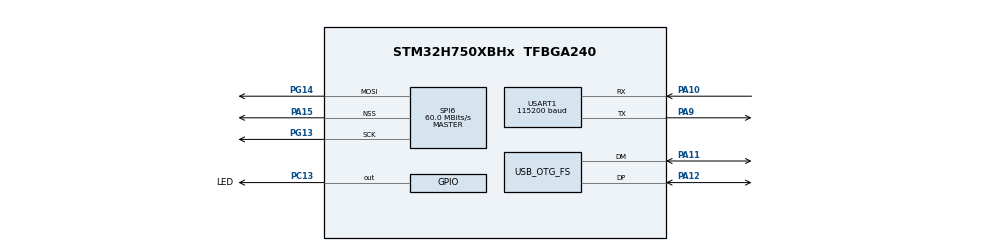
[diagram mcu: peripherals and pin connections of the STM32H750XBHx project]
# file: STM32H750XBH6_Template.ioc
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Bdma.Request0=SPI6_TX
Bdma.RequestsNb=1
Bdma.SPI6_TX.0.Direction=DMA_MEMORY_TO_PERIPH
Bdma.SPI6_TX.0.EventEnable=DISABLE
Bdma.SPI6_TX.0.Instance=BDMA_Channel0
Bdma.SPI6_TX.0.MemDataAlignment=DMA_MDATAALIGN_BYTE
Bdma.SPI6_TX.0.MemInc=DMA_MINC_ENABLE
Bdma.SPI6_TX.0.Mode=DMA_NORMAL
Bdma.SPI6_TX.0.PeriphDataAlignment=DMA_PDATAALIGN_BYTE
Bdma.SPI6_TX.0.PeriphInc=DMA_PINC_DISABLE
Bdma.SPI6_TX.0.Polarity=HAL_DMAMUX_REQ_GEN_RISING
Bdma.SPI6_TX.0.Priority=DMA_PRIORITY_VERY_HIGH
Bdma.SPI6_TX.0.RequestNumber=1
Bdma.SPI6_TX.0.SignalID=NONE
Bdma.SPI6_TX.0.SyncEnable=DISABLE
Bdma.SPI6_TX.0.SyncPolarity=HAL_DMAMUX_SYNC_NO_EVENT
Bdma.SPI6_TX.0.SyncRequestNumber=1
Bdma.SPI6_TX.0.SyncSignalID=NONE
CORTEX_M7.CPU_DCache=Disabled
CORTEX_M7.CPU_ICache=Disabled
CORTEX_M7.MPU_Control=__NULL
CORTEX_M7.default_mode_Activation=0
Mcu.Family=STM32H7
Mcu.Name=STM32H750XBHx
Mcu.Package=TFBGA240
NVIC.BDMA_Channel0_IRQn=true\:0\:0\:false\:false\:true\:false\:true\:true
NVIC.OTG_FS_IRQn=true\:0\:0\:false\:false\:true\:false\:true\:true
NVIC.PriorityGroup=NVIC_PRIORITYGROUP_4
NVIC.SPI6_IRQn=true\:0\:0\:false\:false\:true\:false\:true\:true
NVIC.USART1_IRQn=true\:1\:0\:true\:false\:true\:true\:true\:true
PA10.Mode=Asynchronous
PA10.Signal=USART1_RX
PA11.Mode=Device_Only
PA11.Signal=USB_OTG_FS_DM
PA12.Mode=Device_Only
PA12.Signal=USB_OTG_FS_DP
PA13\ (JTMS/SWDIO).Mode=Serial_Wire
PA13\ (JTMS/SWDIO).Signal=DEBUG_JTMS-SWDIO
PA14\ (JTCK/SWCLK).Mode=Serial_Wire
PA14\ (JTCK/SWCLK).Signal=DEBUG_JTCK-SWCLK
PA15\ (JTDI).GPIO_Speed=GPIO_SPEED_FREQ_VERY_HIGH
PA15\ (JTDI).Mode=NSS_Signal_Hard_Output
PA15\ (JTDI).Signal=SPI6_NSS
PA9.Mode=Asynchronous
PA9.Signal=USART1_TX
PC13.GPIO_Label=LED
PC13.PinState=GPIO_PIN_SET
PC13.Signal=GPIO_Output
PC14-OSC32_IN\ (OSC32_IN).Mode=LSE-External-Oscillator
PC14-OSC32_IN\ (OSC32_IN).Signal=RCC_OSC32_IN
PC15-OSC32_OUT\ (OSC32_OUT).Mode=LSE-External-Oscillator
PC15-OSC32_OUT\ (OSC32_OUT).Signal=RCC_OSC32_OUT
PG13.GPIO_Speed=GPIO_SPEED_FREQ_VERY_HIGH
PG13.Mode=TX_Only_Simplex_Unidirect_Master
PG13.Signal=SPI6_SCK
PG14.GPIO_Speed=GPIO_SPEED_FREQ_VERY_HIGH
PG14.Mode=TX_Only_Simplex_Unidirect_Master
PG14.Signal=SPI6_MOSI
PH0-OSC_IN\ (PH0).Mode=HSE-External-Oscillator
PH0-OSC_IN\ (PH0).Signal=RCC_OSC_IN
PH1-OSC_OUT\ (PH1).Mode=HSE-External-Oscillator
PH1-OSC_OUT\ (PH1).Signal=RCC_OSC_OUT
ProjectManager.HeapSize=0x200
ProjectManager.StackSize=0x400
ProjectManager.TargetToolchain=CMake
RCC.ADCFreq_Value=480000000
RCC.APB1Freq_Value=120000000
RCC.APB2Freq_Value=120000000
RCC.APB3Freq_Value=120000000
RCC.APB4Freq_Value=120000000
RCC.CortexFreq_Value=480000000
RCC.D1PPRE=RCC_APB3_DIV2
RCC.D2PPRE1=RCC_APB1_DIV2
RCC.D2PPRE2=RCC_APB2_DIV2
RCC.D3PPRE=RCC_APB4_DIV2
RCC.DIVM1=5
RCC.DIVM2=5
RCC.DIVM3=5
RCC.DIVN1=192
RCC.DIVN2=192
RCC.DIVN3=192
RCC.FLatency=FLASH_LATENCY_4
RCC.HCLKFreq_Value=240000000
RCC.HPRE=RCC_HCLK_DIV2
RCC.PLL1_VCI_Range=RCC_PLL1VCIRANGE_2
RCC.PLL2FRACN=0
RCC.PLL3FRACN=0
RCC.PLLFRACN=0
RCC.PLLSourceVirtual=RCC_PLLSOURCE_HSE
RCC.PWR_Regulator_Voltage_Scale=PWR_REGULATOR_VOLTAGE_SCALE0
RCC.ProductRev=revV
RCC.SYSCLKFreq_VALUE=480000000
RCC.SYSCLKSource=RCC_SYSCLKSOURCE_PLLCLK
RCC.USBCLockSelection=RCC_USBCLKSOURCE_HSI48
RCC.USBFreq_Value=48000000
SPI6.CalculateBaudRate=60.0 MBits/s
SPI6.DataSize=SPI_DATASIZE_8BIT
SPI6.Direction=SPI_DIRECTION_2LINES_TXONLY
SPI6.Mode=SPI_MODE_MASTER
SPI6.VirtualNSS=VM_NSSHARD
SPI6.VirtualType=VM_MASTER
USART1.AutoBaudRateEnableParam=UART_ADVFEATURE_AUTOBAUDRATE_DISABLE
USART1.BaudRate=115200
USART1.ClockPrescaler=PRESCALER_DIV1
USART1.DMADisableonRxErrorParam=ADVFEATURE_DMA_ENABLEONRXERROR
USART1.DataInvertParam=ADVFEATURE_DATAINV_DISABLE
USART1.FIFOMode=FIFOMODE_DISABLE
USART1.MSBFirstParam=ADVFEATURE_MSBFIRST_DISABLE
USART1.Mode=MODE_TX_RX
USART1.OneBitSampling=UART_ONE_BIT_SAMPLE_DISABLE
USART1.OverSampling=UART_OVERSAMPLING_16
USART1.OverrunDisableParam=ADVFEATURE_OVERRUN_ENABLE
USART1.Parity=PARITY_NONE
USART1.RXFIFOThreshold=RXFIFO_THRESHOLD_1EIGHTHFULL
USART1.RxPinLevelInvertParam=ADVFEATURE_RXINV_DISABLE
USART1.StopBits=STOPBITS_1
USART1.SwapParam=ADVFEATURE_SWAP_DISABLE
USART1.TXFIFOThreshold=TXFIFO_THRESHOLD_1EIGHTHFULL
USART1.TxPinLevelInvertParam=ADVFEATURE_TXINV_DISABLE
USART1.VirtualMode-Asynchronous=VM_ASYNC
USART1.WordLength=WORDLENGTH_8B
USB_DEVICE.CLASS_NAME_FS=CDC
USB_DEVICE.VirtualMode-CDC_FS=Cdc
USB_DEVICE.VirtualModeFS=Cdc_FS
USB_OTG_FS.VirtualMode=Device_Only
VP_MEMORYMAP_VS_MEMORYMAP.Mode=CurAppReg
VP_USB_DEVICE_VS_USB_DEVICE_CDC_FS.Mode=CDC_FS
board=custom

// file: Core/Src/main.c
/* USER CODE BEGIN Header */
/**
 ******************************************************************************
 * @file           : main.c
 * @brief          : Main program body
 ******************************************************************************
 * @attention
 *
 * Copyright (c) 2025 STMicroelectronics.
 * All rights reserved.
 *
 * This software is licensed under terms that can be found in the LICENSE file
 * in the root directory of this software component.
 * If no LICENSE file comes with this software, it is provided AS-IS.
 *
 ******************************************************************************
 */
/* USER CODE END Header */
#include "main.h"
#include "bdma.h"
#include "spi.h"
#include "usart.h"
#include "usb_device.h"
#include "gpio.h"

/* USER CODE BEGIN Includes */
#include "lcd_spi_200.h"
#include "retarget.h" //重定向printf
#include "usbd_cdc_if.h"
#include "user_code_interface.h"
/* USER CODE END Includes */

void SystemClock_Config(void);

int main(void)
{

  /* MCU Configuration--------------------------------------------------------*/

  /* Reset of all peripherals, Initializes the Flash interface and the Systick. */
  HAL_Init();

  /* Configure the system clock */
  SystemClock_Config();

  /* Initialize all configured peripherals */
  MX_GPIO_Init();
  MX_BDMA_Init();
  MX_USART1_UART_Init();
  MX_USB_DEVICE_Init();
  MX_SPI6_Init();
  /* USER CODE BEGIN 2 */
    RetargetInit(&huart1); // 重定向printf
    SPI_LCD_Init();

    printf("现在进行刷屏测试\n");
    User_Code_Entry();

  /* USER CODE END 2 */

  /* Infinite loop */
    while (1)
    {

    /* USER CODE BEGIN 3 */
        // LCD_Test_Clear(); // 清屏测试
        // LCD_Test_Text(); // 文本测试
        // LCD_Test_Variable(); // 变量显示，包括整数和小数
        // LCD_Test_Color(); // 颜色测试
        // LCD_Test_Grahic(); // 2D图形绘制
        // LCD_Test_Image(); // 图片显示
        // LCD_Test_Direction(); // 更换显示方向
        HAL_Delay(500);
        printf("hello, world!\n");
    }
  /* USER CODE END 3 */
}

void SystemClock_Config(void)
{
  RCC_OscInitTypeDef RCC_OscInitStruct = {0};
  RCC_ClkInitTypeDef RCC_ClkInitStruct = {0};

  /** Supply configuration update enable
  */
  HAL_PWREx_ConfigSupply(PWR_LDO_SUPPLY);

  /** Configure the main internal regulator output voltage
  */
  __HAL_PWR_VOLTAGESCALING_CONFIG(PWR_REGULATOR_VOLTAGE_SCALE0);

  while(!__HAL_PWR_GET_FLAG(PWR_FLAG_VOSRDY)) {}

  /** Initializes the RCC Oscillators according to the specified parameters
  * in the RCC_OscInitTypeDef structure.
  */
  RCC_OscInitStruct.OscillatorType = RCC_OSCILLATORTYPE_HSI48|RCC_OSCILLATORTYPE_HSE;
  RCC_OscInitStruct.HSEState = RCC_HSE_ON;
  RCC_OscInitStruct.HSI48State = RCC_HSI48_ON;
  RCC_OscInitStruct.PLL.PLLState = RCC_PLL_ON;
  RCC_OscInitStruct.PLL.PLLSource = RCC_PLLSOURCE_HSE;
  RCC_OscInitStruct.PLL.PLLM = 5;
  RCC_OscInitStruct.PLL.PLLN = 192;
  RCC_OscInitStruct.PLL.PLLP = 2;
  RCC_OscInitStruct.PLL.PLLQ = 2;
  RCC_OscInitStruct.PLL.PLLR = 2;
  RCC_OscInitStruct.PLL.PLLRGE = RCC_PLL1VCIRANGE_2;
  RCC_OscInitStruct.PLL.PLLVCOSEL = RCC_PLL1VCOWIDE;
  RCC_OscInitStruct.PLL.PLLFRACN = 0;
  if (HAL_RCC_OscConfig(&RCC_OscInitStruct) != HAL_OK)
  {
    Error_Handler();
  }

  /** Initializes the CPU, AHB and APB buses clocks
  */
  RCC_ClkInitStruct.ClockType = RCC_CLOCKTYPE_HCLK|RCC_CLOCKTYPE_SYSCLK
                              |RCC_CLOCKTYPE_PCLK1|RCC_CLOCKTYPE_PCLK2
                              |RCC_CLOCKTYPE_D3PCLK1|RCC_CLOCKTYPE_D1PCLK1;
  RCC_ClkInitStruct.SYSCLKSource = RCC_SYSCLKSOURCE_PLLCLK;
  RCC_ClkInitStruct.SYSCLKDivider = RCC_SYSCLK_DIV1;
  RCC_ClkInitStruct.AHBCLKDivider = RCC_HCLK_DIV2;
  RCC_ClkInitStruct.APB3CLKDivider = RCC_APB3_DIV2;
  RCC_ClkInitStruct.APB1CLKDivider = RCC_APB1_DIV2;
  RCC_ClkInitStruct.APB2CLKDivider = RCC_APB2_DIV2;
  RCC_ClkInitStruct.APB4CLKDivider = RCC_APB4_DIV2;

  if (HAL_RCC_ClockConfig(&RCC_ClkInitStruct, FLASH_LATENCY_4) != HAL_OK)
  {
    Error_Handler();
  }
}

void Error_Handler(void)
{
    __disable_irq();
    while (1)
    {
    }
}
